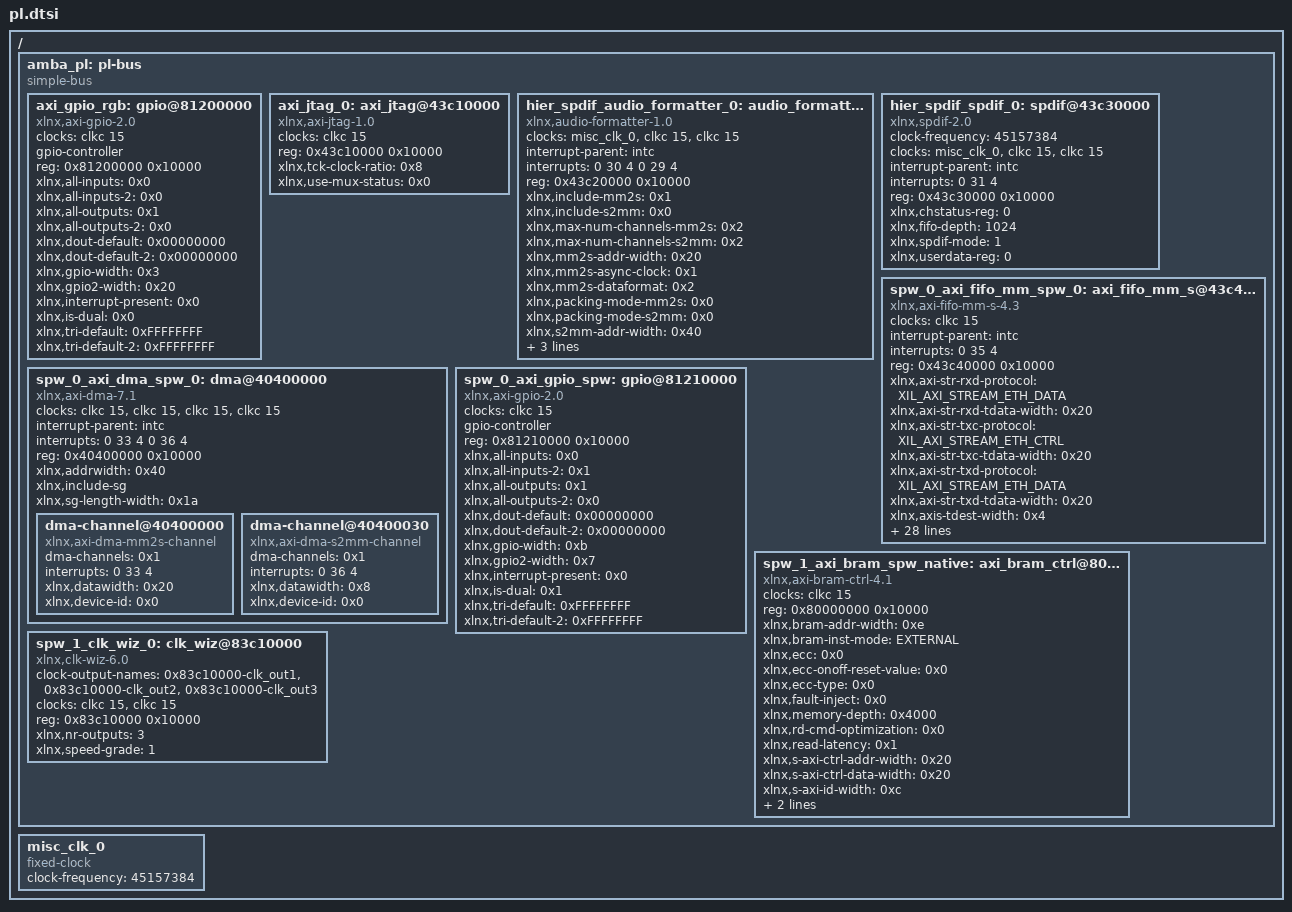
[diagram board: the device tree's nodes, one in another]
/*
 * CAUTION: This file is automatically generated by Xilinx.
 * Version: XSCT 
 * Today is: Thu Jan 15 14:26:06 2026
 */


/ {
	amba_pl: pl-bus {
		#address-cells = <1>;
		#size-cells = <1>;
		compatible = "simple-bus";
		ranges ;
		axi_gpio_rgb: gpio@81200000 {
			#gpio-cells = <2>;
			clock-names = "s_axi_aclk";
			clocks = <&clkc 15>;
			compatible = "xlnx,axi-gpio-2.0", "xlnx,xps-gpio-1.00.a";
			gpio-controller ;
			reg = <0x81200000 0x10000>;
			xlnx,all-inputs = <0x0>;
			xlnx,all-inputs-2 = <0x0>;
			xlnx,all-outputs = <0x1>;
			xlnx,all-outputs-2 = <0x0>;
			xlnx,dout-default = <0x00000000>;
			xlnx,dout-default-2 = <0x00000000>;
			xlnx,gpio-width = <0x3>;
			xlnx,gpio2-width = <0x20>;
			xlnx,interrupt-present = <0x0>;
			xlnx,is-dual = <0x0>;
			xlnx,tri-default = <0xFFFFFFFF>;
			xlnx,tri-default-2 = <0xFFFFFFFF>;
		};
		axi_jtag_0: axi_jtag@43c10000 {
			clock-names = "s_axi_aclk";
			clocks = <&clkc 15>;
			compatible = "xlnx,axi-jtag-1.0";
			reg = <0x43c10000 0x10000>;
			xlnx,tck-clock-ratio = <0x8>;
			xlnx,use-mux-status = <0x0>;
		};
		hier_spdif_audio_formatter_0: audio_formatter@43c20000 {
			clock-names = "aud_mclk", "m_axis_mm2s_aclk", "s_axi_lite_aclk";
			clocks = <&misc_clk_0>, <&clkc 15>, <&clkc 15>;
			compatible = "xlnx,audio-formatter-1.0", "xlnx,audio-formatter-1.0";
			interrupt-names = "irq_mm2s", "irq_s2mm";
			interrupt-parent = <&intc>;
			interrupts = <0 30 4 0 29 4>;
			reg = <0x43c20000 0x10000>;
			xlnx,include-mm2s = <0x1>;
			xlnx,include-s2mm = <0x0>;
			xlnx,max-num-channels-mm2s = <0x2>;
			xlnx,max-num-channels-s2mm = <0x2>;
			xlnx,mm2s-addr-width = <0x20>;
			xlnx,mm2s-async-clock = <0x1>;
			xlnx,mm2s-dataformat = <0x2>;
			xlnx,packing-mode-mm2s = <0x0>;
			xlnx,packing-mode-s2mm = <0x0>;
			xlnx,s2mm-addr-width = <0x40>;
			xlnx,s2mm-async-clock = <0x1>;
			xlnx,s2mm-dataformat = <0x1>;
			xlnx,tx = <&hier_spdif_axis_subset_converter_0>;
		};
		hier_spdif_spdif_0: spdif@43c30000 {
			clock-frequency = <45157384>;
			clock-names = "aud_clk_i", "s_axi_aclk", "s_axis_aclk";
			clocks = <&misc_clk_0>, <&clkc 15>, <&clkc 15>;
			compatible = "xlnx,spdif-2.0", "xlnx,spdif-2.0";
			interrupt-names = "spdif_interrupt";
			interrupt-parent = <&intc>;
			interrupts = <0 31 4>;
			reg = <0x43c30000 0x10000>;
			xlnx,chstatus-reg = <0>;
			xlnx,fifo-depth = <1024>;
			xlnx,spdif-mode = <1>;
			xlnx,userdata-reg = <0>;
		};
		spw_0_axi_dma_spw_0: dma@40400000 {
			#dma-cells = <1>;
			clock-names = "m_axi_mm2s_aclk", "m_axi_s2mm_aclk", "m_axi_sg_aclk", "s_axi_lite_aclk";
			clocks = <&clkc 15>, <&clkc 15>, <&clkc 15>, <&clkc 15>;
			compatible = "xlnx,axi-dma-7.1", "xlnx,axi-dma-1.00.a";
			interrupt-names = "mm2s_introut", "s2mm_introut";
			interrupt-parent = <&intc>;
			interrupts = <0 33 4 0 36 4>;
			reg = <0x40400000 0x10000>;
			xlnx,addrwidth = <0x40>;
			xlnx,include-sg ;
			xlnx,sg-length-width = <0x1a>;
			dma-channel@40400000 {
				compatible = "xlnx,axi-dma-mm2s-channel";
				dma-channels = <0x1>;
				interrupts = <0 33 4>;
				xlnx,datawidth = <0x20>;
				xlnx,device-id = <0x0>;
			};
			dma-channel@40400030 {
				compatible = "xlnx,axi-dma-s2mm-channel";
				dma-channels = <0x1>;
				interrupts = <0 36 4>;
				xlnx,datawidth = <0x8>;
				xlnx,device-id = <0x0>;
			};
		};
		spw_0_axi_fifo_mm_spw_0: axi_fifo_mm_s@43c40000 {
			clock-names = "s_axi_aclk";
			clocks = <&clkc 15>;
			compatible = "xlnx,axi-fifo-mm-s-4.3";
			interrupt-names = "interrupt";
			interrupt-parent = <&intc>;
			interrupts = <0 35 4>;
			reg = <0x43c40000 0x10000>;
			xlnx,axi-str-rxd-protocol = "XIL_AXI_STREAM_ETH_DATA";
			xlnx,axi-str-rxd-tdata-width = <0x20>;
			xlnx,axi-str-txc-protocol = "XIL_AXI_STREAM_ETH_CTRL";
			xlnx,axi-str-txc-tdata-width = <0x20>;
			xlnx,axi-str-txd-protocol = "XIL_AXI_STREAM_ETH_DATA";
			xlnx,axi-str-txd-tdata-width = <0x20>;
			xlnx,axis-tdest-width = <0x4>;
			xlnx,axis-tid-width = <0x4>;
			xlnx,axis-tuser-width = <0x4>;
			xlnx,data-interface-type = <0x0>;
			xlnx,has-axis-tdest = <0x0>;
			xlnx,has-axis-tid = <0x0>;
			xlnx,has-axis-tkeep = <0x1>;
			xlnx,has-axis-tstrb = <0x0>;
			xlnx,has-axis-tuser = <0x0>;
			xlnx,rx-cascade-height = <0x0>;
			xlnx,rx-enable-ecc = <0x0>;
			xlnx,rx-fifo-depth = <0x200>;
			xlnx,rx-fifo-pe-threshold = <0x5>;
			xlnx,rx-fifo-pf-threshold = <0x1fb>;
			xlnx,rx-has-ecc-err-inject = <0x0>;
			xlnx,s-axi-id-width = <0x4>;
			xlnx,s-axi4-data-width = <0x20>;
			xlnx,select-xpm = <0x0>;
			xlnx,tx-cascade-height = <0x0>;
			xlnx,tx-enable-ecc = <0x0>;
			xlnx,tx-fifo-depth = <0x400>;
			xlnx,tx-fifo-pe-threshold = <0x5>;
			xlnx,tx-fifo-pf-threshold = <0x1fb>;
			xlnx,tx-has-ecc-err-inject = <0x0>;
			xlnx,use-rx-cut-through = <0x0>;
			xlnx,use-rx-data = <0x1>;
			xlnx,use-tx-ctrl = <0x0>;
			xlnx,use-tx-cut-through = <0x0>;
			xlnx,use-tx-data = <0x1>;
		};
		spw_0_axi_gpio_spw: gpio@81210000 {
			#gpio-cells = <2>;
			clock-names = "s_axi_aclk";
			clocks = <&clkc 15>;
			compatible = "xlnx,axi-gpio-2.0", "xlnx,xps-gpio-1.00.a";
			gpio-controller ;
			reg = <0x81210000 0x10000>;
			xlnx,all-inputs = <0x0>;
			xlnx,all-inputs-2 = <0x1>;
			xlnx,all-outputs = <0x1>;
			xlnx,all-outputs-2 = <0x0>;
			xlnx,dout-default = <0x00000000>;
			xlnx,dout-default-2 = <0x00000000>;
			xlnx,gpio-width = <0xb>;
			xlnx,gpio2-width = <0x7>;
			xlnx,interrupt-present = <0x0>;
			xlnx,is-dual = <0x1>;
			xlnx,tri-default = <0xFFFFFFFF>;
			xlnx,tri-default-2 = <0xFFFFFFFF>;
		};
		spw_1_axi_bram_spw_native: axi_bram_ctrl@80000000 {
			clock-names = "s_axi_aclk";
			clocks = <&clkc 15>;
			compatible = "xlnx,axi-bram-ctrl-4.1";
			reg = <0x80000000 0x10000>;
			xlnx,bram-addr-width = <0xe>;
			xlnx,bram-inst-mode = "EXTERNAL";
			xlnx,ecc = <0x0>;
			xlnx,ecc-onoff-reset-value = <0x0>;
			xlnx,ecc-type = <0x0>;
			xlnx,fault-inject = <0x0>;
			xlnx,memory-depth = <0x4000>;
			xlnx,rd-cmd-optimization = <0x0>;
			xlnx,read-latency = <0x1>;
			xlnx,s-axi-ctrl-addr-width = <0x20>;
			xlnx,s-axi-ctrl-data-width = <0x20>;
			xlnx,s-axi-id-width = <0xc>;
			xlnx,s-axi-supports-narrow-burst = <0x0>;
			xlnx,single-port-bram = <0x1>;
		};
		spw_1_clk_wiz_0: clk_wiz@83c10000 {
			#clock-cells = <1>;
			clock-names = "clk_in1", "s_axi_aclk";
			clock-output-names = "0x83c10000-clk_out1", "0x83c10000-clk_out2", "0x83c10000-clk_out3";
			clocks = <&clkc 15>, <&clkc 15>;
			compatible = "xlnx,clk-wiz-6.0", "xlnx,clocking-wizard";
			reg = <0x83c10000 0x10000>;
			xlnx,nr-outputs = <3>;
			xlnx,speed-grade = <1>;
		};
	};
	misc_clk_0: misc_clk_0 {
		#clock-cells = <0>;
		clock-frequency = <45157384>;
		compatible = "fixed-clock";
	};
};
